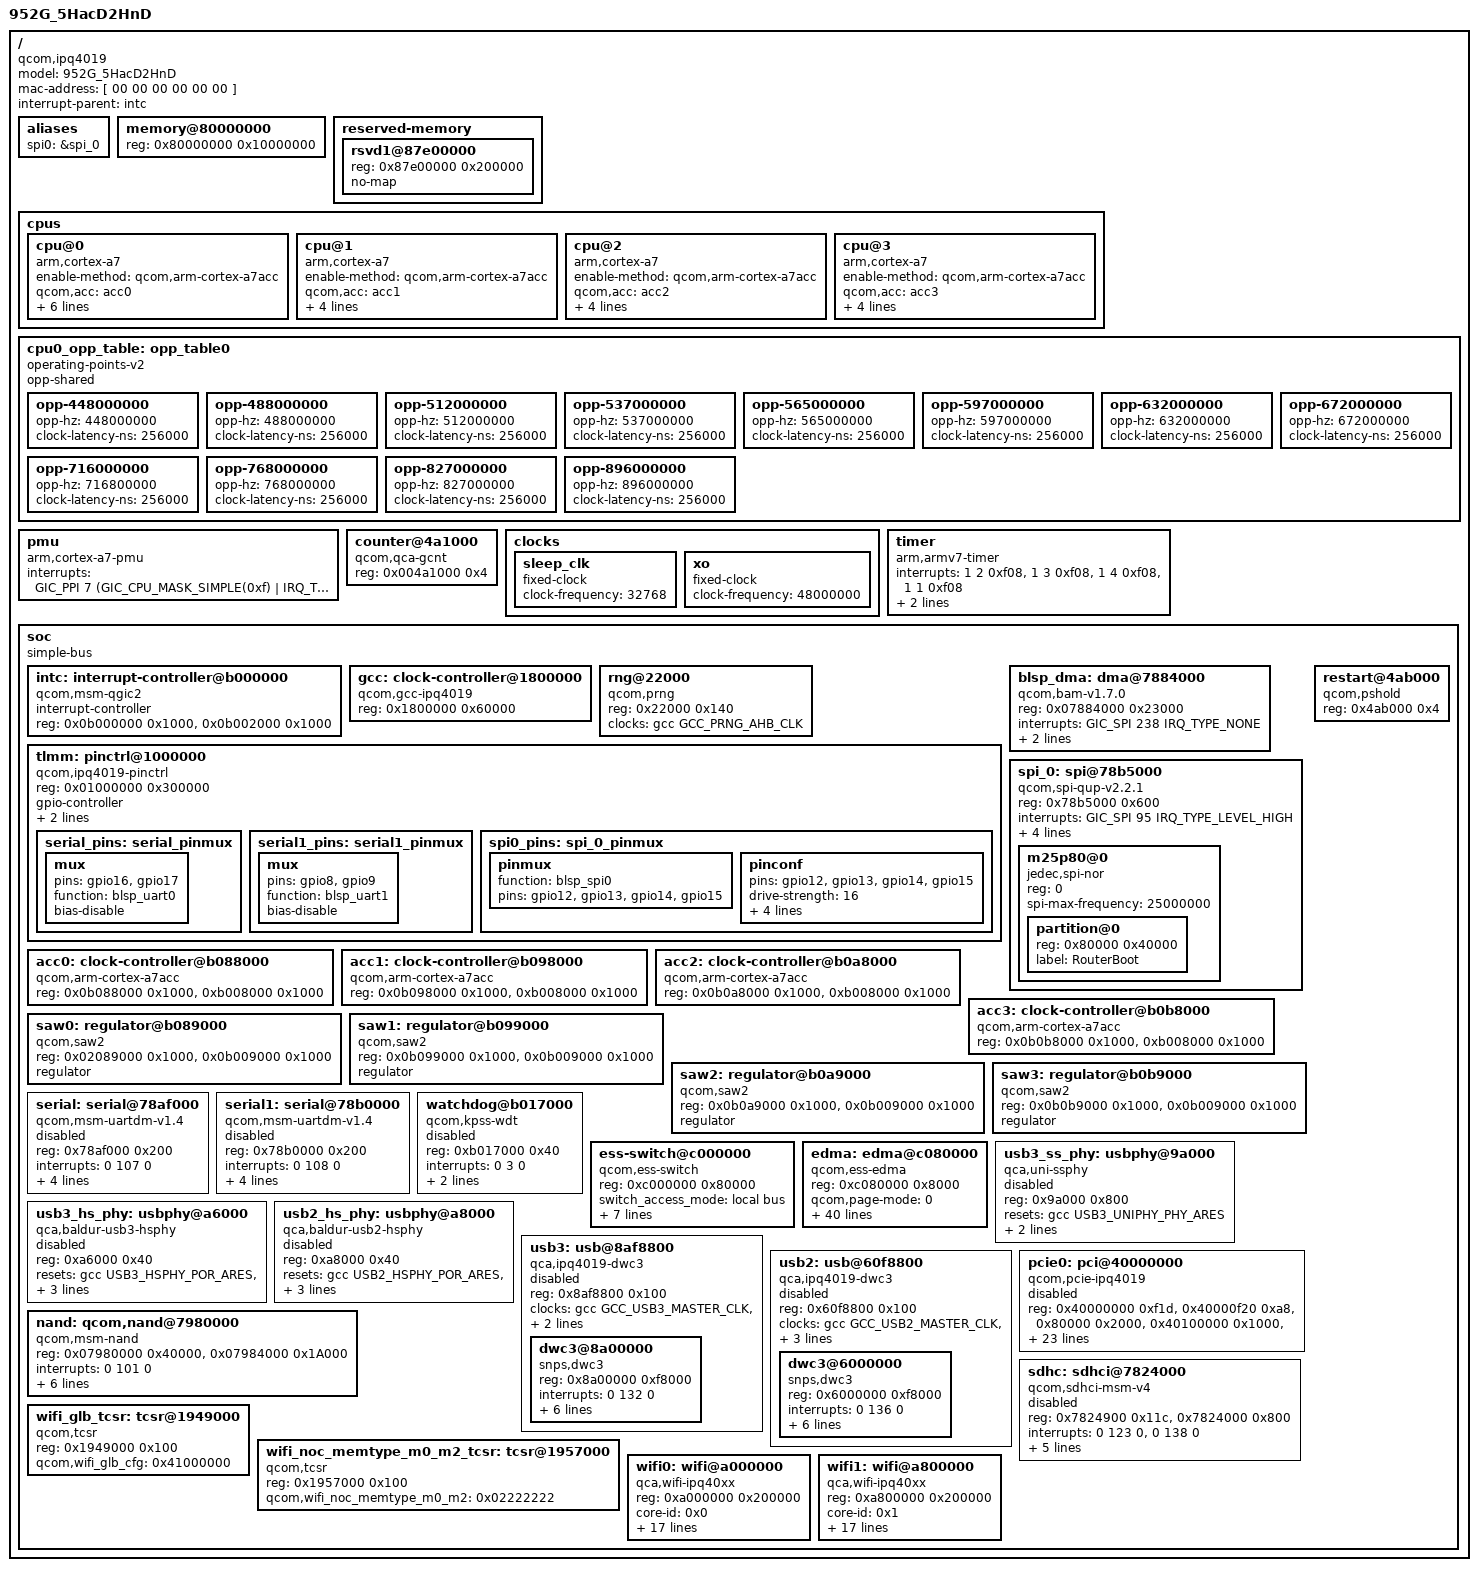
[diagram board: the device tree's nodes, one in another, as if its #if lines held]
#include <dt-bindings/clock/qcom,gcc-ipq4019.h>
#include <dt-bindings/interrupt-controller/arm-gic.h>
#include <dt-bindings/interrupt-controller/irq.h>
#include <dt-bindings/gpio/gpio.h>
#include "dakota_crypto.dtsi"

/ {
	#address-cells = <1>;
	#size-cells = <1>;
	
	model = "952G_5HacD2HnD";
	compatible = "qcom,ipq4019";
	mac-address = [ 00 00 00 00 00 00 ];
	interrupt-parent = <&intc>;

	aliases {
		spi0 = &spi_0;
	};

	memory@80000000 {
		device_type = "memory";
		reg = <0x80000000 0x10000000>; /* 256MB */
	};

	reserved-memory {
		#address-cells = <1>;
		#size-cells = <1>;
		ranges;
		rsvd1@87e00000 {
			reg = <0x87e00000 0x200000>;
			no-map;
		};
	};

	cpus {
		#address-cells = <1>;
		#size-cells = <0>;
		cpu@0 {
			device_type = "cpu";
			compatible = "arm,cortex-a7";
			enable-method = "qcom,arm-cortex-a7acc";
			qcom,acc = <&acc0>;
			qcom,saw = <&saw0>;
			reg = <0x0>;
			clocks = <&gcc GCC_APPS_CLK_SRC>;
			clock-frequency = <0>;
			operating-points-v2 = <&cpu0_opp_table>;
			clock-latency = <256000>;
		};

		cpu@1 {
			device_type = "cpu";
			compatible = "arm,cortex-a7";
			enable-method = "qcom,arm-cortex-a7acc";
			qcom,acc = <&acc1>;
			qcom,saw = <&saw1>;
			reg = <0x1>;
			clocks = <&gcc GCC_APPS_CLK_SRC>;
			clock-frequency = <0>;
		};

		cpu@2 {
			device_type = "cpu";
			compatible = "arm,cortex-a7";
			enable-method = "qcom,arm-cortex-a7acc";
			qcom,acc = <&acc2>;
			qcom,saw = <&saw2>;
			reg = <0x2>;
			clocks = <&gcc GCC_APPS_CLK_SRC>;
			clock-frequency = <0>;
		};

		cpu@3 {
			device_type = "cpu";
			compatible = "arm,cortex-a7";
			enable-method = "qcom,arm-cortex-a7acc";
			qcom,acc = <&acc3>;
			qcom,saw = <&saw3>;
			reg = <0x3>;
			clocks = <&gcc GCC_APPS_CLK_SRC>;
			clock-frequency = <0>;
		};
	};

	cpu0_opp_table: opp_table0 {
		compatible = "operating-points-v2";
		opp-shared;

		opp-448000000 {
			opp-hz = /bits/ 64 <448000000>;
			clock-latency-ns = <256000>;
		};
		opp-488000000 {
			opp-hz = /bits/ 64 <488000000>;
			clock-latency-ns = <256000>;
		};
		opp-512000000 {
			opp-hz = /bits/ 64 <512000000>;
			clock-latency-ns = <256000>;
		};
		opp-537000000 {
			opp-hz = /bits/ 64 <537000000>;
			clock-latency-ns = <256000>;
		};
		opp-565000000 {
			opp-hz = /bits/ 64 <565000000>;
			clock-latency-ns = <256000>;
		};
		opp-597000000 {
			opp-hz = /bits/ 64 <597000000>;
			clock-latency-ns = <256000>;
		};
		opp-632000000 {
			opp-hz = /bits/ 64 <632000000>;
			clock-latency-ns = <256000>;
		};
		opp-672000000 {
			opp-hz = /bits/ 64 <672000000>;
			clock-latency-ns = <256000>;
		};
		opp-716000000 {
			opp-hz = /bits/ 64 <716800000>;
			clock-latency-ns = <256000>;
		};
		opp-768000000 {
			opp-hz = /bits/ 64 <768000000>;
			clock-latency-ns = <256000>;
		};
		opp-827000000 {
			opp-hz = /bits/ 64 <827000000>;
			clock-latency-ns = <256000>;
		};
		opp-896000000 {
			opp-hz = /bits/ 64 <896000000>;
			clock-latency-ns = <256000>;
		};
	};

	pmu {
		compatible = "arm,cortex-a7-pmu";
		interrupts = <GIC_PPI 7 (GIC_CPU_MASK_SIMPLE(0xf) |
					 IRQ_TYPE_LEVEL_HIGH)>;
	};

	counter@4a1000 {
		compatible = "qcom,qca-gcnt";
		reg = <0x004a1000 0x4>;
	};

	clocks {
		sleep_clk: sleep_clk {
			compatible = "fixed-clock";
			clock-frequency = <32768>;
			#clock-cells = <0>;
		};

		xo: xo {
			compatible = "fixed-clock";
			clock-frequency = <48000000>;
			#clock-cells = <0>;
		};
	};

	timer {
		compatible = "arm,armv7-timer";
		interrupts = <1 2 0xf08>,
			     <1 3 0xf08>,
			     <1 4 0xf08>,
			     <1 1 0xf08>;
		clock-frequency = <48000000>;
		always-on;
	};

	soc: soc {
		#address-cells = <1>;
		#size-cells = <1>;
		ranges;
		compatible = "simple-bus";

		intc: interrupt-controller@b000000 {
			compatible = "qcom,msm-qgic2";
			interrupt-controller;
			#interrupt-cells = <3>;
			reg = <0x0b000000 0x1000>,
			<0x0b002000 0x1000>;
		};

		gcc: clock-controller@1800000 {
			compatible = "qcom,gcc-ipq4019";
			#clock-cells = <1>;
			#reset-cells = <1>;
			reg = <0x1800000 0x60000>;
		};

		rng@22000 {
			compatible = "qcom,prng";
			reg = <0x22000 0x140>;
			clocks = <&gcc GCC_PRNG_AHB_CLK>;
			clock-names = "core";
		};

		tlmm: pinctrl@1000000 {
			compatible = "qcom,ipq4019-pinctrl";
			reg = <0x01000000 0x300000>;
			gpio-controller;
			#gpio-cells = <2>;
			interrupt-controller;
			#interrupt-cells = <2>;
			interrupts = <0 208 0>;

			serial_pins: serial_pinmux {
				mux {
#ifdef BIG_DK 
					pins = "gpio16", "gpio17";
					function = "blsp_uart0";
					bias-disable;
#else
					pins = "gpio60", "gpio61";
					function = "blsp_uart0";
					bias-disable;
#endif
				};
			};

			serial1_pins: serial1_pinmux {
				mux {
					pins = "gpio8", "gpio9";
					function = "blsp_uart1";
					bias-disable;
				};
			};

			spi0_pins: spi_0_pinmux {
#ifdef BIG_DK 
				pinmux {
					function = "blsp_spi0";
					pins = "gpio12", "gpio13", "gpio14", "gpio15";
				};
				pinconf {
					pins = "gpio12", "gpio13", "gpio14", "gpio15";
					drive-strength = <16>;
					bias-pull-up;
					bias-pull-down;
					vm-enable;
					pull-res = <2>;
				};
#else
				pinmux {
					function = "blsp_spi0";
					pins = "gpio54", "gpio55", "gpio56", "gpio57";
				};
				pinconf {
					pins = "gpio54", "gpio55", "gpio56", "gpio57";
					drive-strength = <16>;
					bias-pull-up;
					bias-pull-down;
					vm-enable;
					pull-res = <2>;
				};
#endif
			};
		};

		blsp_dma: dma@7884000 {
			compatible = "qcom,bam-v1.7.0";
			reg = <0x07884000 0x23000>;
			interrupts = <GIC_SPI 238 IRQ_TYPE_NONE>;
			clocks = <&gcc GCC_BLSP1_AHB_CLK>;
			clock-names = "bam_clk";
			#dma-cells = <1>;
			qcom,ee = <0>;
		};

		spi_0: spi@78b5000 {
			compatible = "qcom,spi-qup-v2.2.1";
			reg = <0x78b5000 0x600>;
			interrupts = <GIC_SPI 95 IRQ_TYPE_LEVEL_HIGH>;
			clocks = <&gcc GCC_BLSP1_QUP1_SPI_APPS_CLK>,
				 <&gcc GCC_BLSP1_AHB_CLK>;
			clock-names = "core", "iface";
			#address-cells = <1>;
			#size-cells = <0>;

			dmas = <&blsp_dma 5>, <&blsp_dma 4>;
			dma-names = "rx", "tx";

			pinctrl-0 = <&spi0_pins>;
			pinctrl-names = "default";

			m25p80@0 {
				#address-cells = <1>;
				#size-cells = <1>;
				compatible = "jedec,spi-nor";
				reg = <0>;
				spi-max-frequency = <25000000>;

#ifdef NAND
				partition@0 {
					reg = <0x80000 0x40000>;
					label = "RouterBoot";
				};
#else
				partition@0 {
					reg = <0x100000 0>;
					label = "RouterOS";
				};
				partition@1 {
					reg = <0x80000 0x40000>;
					label = "RouterBoot";
				};
#endif
			};
		};

                acc0: clock-controller@b088000 {
                        compatible = "qcom,arm-cortex-a7acc";
                        reg = <0x0b088000 0x1000>, <0xb008000 0x1000>;
                };

                acc1: clock-controller@b098000 {
                        compatible = "qcom,arm-cortex-a7acc";
                        reg = <0x0b098000 0x1000>, <0xb008000 0x1000>;
                };

                acc2: clock-controller@b0a8000 {
                        compatible = "qcom,arm-cortex-a7acc";
                        reg = <0x0b0a8000 0x1000>, <0xb008000 0x1000>;
                };

                acc3: clock-controller@b0b8000 {
                        compatible = "qcom,arm-cortex-a7acc";
                        reg = <0x0b0b8000 0x1000>, <0xb008000 0x1000>;
                };

                saw0: regulator@b089000 {
                        compatible = "qcom,saw2";
                        reg = <0x02089000 0x1000>, <0x0b009000 0x1000>;
                        regulator;
                };

                saw1: regulator@b099000 {
                        compatible = "qcom,saw2";
                        reg = <0x0b099000 0x1000>, <0x0b009000 0x1000>;
                        regulator;
                };

                saw2: regulator@b0a9000 {
                        compatible = "qcom,saw2";
                        reg = <0x0b0a9000 0x1000>, <0x0b009000 0x1000>;
                        regulator;
                };

                saw3: regulator@b0b9000 {
                        compatible = "qcom,saw2";
                        reg = <0x0b0b9000 0x1000>, <0x0b009000 0x1000>;
                        regulator;
                };

		serial: serial@78af000 {
			compatible = "qcom,msm-uartdm-v1.4", "qcom,msm-uartdm";
			reg = <0x78af000 0x200>;
			interrupts = <0 107 0>;
			clocks = <&gcc GCC_BLSP1_UART1_APPS_CLK>,
				<&gcc GCC_BLSP1_AHB_CLK>;
			clock-names = "core", "iface";
			dmas = <&blsp_dma 1>, <&blsp_dma 0>;
			dma-names = "rx", "tx";
			pinctrl-0 = <&serial_pins>;
			pinctrl-names = "default";
			status = "disabled";
		};

		serial1: serial@78b0000 {
			compatible = "qcom,msm-uartdm-v1.4", "qcom,msm-uartdm";
			reg = <0x78b0000 0x200>;
			interrupts = <0 108 0>;
			clocks = <&gcc GCC_BLSP1_UART2_APPS_CLK>,
				<&gcc GCC_BLSP1_AHB_CLK>;
			clock-names = "core", "iface";
			dmas = <&blsp_dma 3>, <&blsp_dma 2>;
			dma-names = "rx", "tx";
			pinctrl-0 = <&serial1_pins>;
			pinctrl-names = "default";
			status = "disabled";
		};

		watchdog@b017000 {
			compatible = "qcom,kpss-wdt",
				     "qcom,kpss-wdt-ipq4019";
			reg = <0xb017000 0x40>;
			interrupt-names = "bark_irq";
			interrupts = <0 3 0>;
			clocks = <&sleep_clk>;
			timeout-sec = <10>;
			status = "disabled";
		};

		restart@4ab000 {
			compatible = "qcom,pshold";
			reg = <0x4ab000 0x4>;
		};
		
		ess-switch@c000000 {
			compatible = "qcom,ess-switch";
			reg = <0xc000000 0x80000>; /* 512KB */
			switch_access_mode = "local bus";
			resets = <&gcc 29>, <&gcc 78>, <&gcc 79>,
			         <&gcc 80>, <&gcc 81>, <&gcc 82>;
			reset-names = "ess_rst","ess_mac1_clk_dis",
				      "ess_mac2_clk_dis","ess_mac3_clk_dis",
				      "ess_mac4_clk_dis", "ess_mac5_clk_dis";
//			clocks = <&gcc GCC_ESS_CLK>;
//			clock-names = "ess_clk";
			switch_cpu_bmp = <0x1>;  /* cpu port bitmap */
			switch_lan_bmp = <0x1e>; /* lan port bitmap */
			switch_wan_bmp = <0x20>; /* wan port bitmap */
			switch_mac_mode = <0x0>; /* mac mode for RGMII RMII */
			switch_initvlas = <0x0007c 0x54>; /* PORT0_STATUS */
		};
		edma: edma@c080000 {
			compatible = "qcom,ess-edma";
			reg = <0xc080000 0x8000>;
			qcom,page-mode = <0>;
			qcom,rx_head_buf_size = <1540>;
			qcom,wan_port_id_mask = <0x10>;
			qcom,mdio_supported;
			qcom,phy_mdio_addr = <4>;
			qcom,poll_required = <1>;
			qcom,forced_speed = <1000>;
			qcom,forced_duplex = <1>;

			interrupts = <0 65 IRQ_TYPE_EDGE_RISING>,
				     <0 66 IRQ_TYPE_EDGE_RISING>,
				     <0 67 IRQ_TYPE_EDGE_RISING>,
				     <0 68 IRQ_TYPE_EDGE_RISING>,
				     <0 69 IRQ_TYPE_EDGE_RISING>,
				     <0 70 IRQ_TYPE_EDGE_RISING>,
				     <0 71 IRQ_TYPE_EDGE_RISING>,
				     <0 72 IRQ_TYPE_EDGE_RISING>,
				     <0 73 IRQ_TYPE_EDGE_RISING>,
				     <0 74 IRQ_TYPE_EDGE_RISING>,
				     <0 75 IRQ_TYPE_EDGE_RISING>,
				     <0 76 IRQ_TYPE_EDGE_RISING>,
				     <0 77 IRQ_TYPE_EDGE_RISING>,
				     <0 78 IRQ_TYPE_EDGE_RISING>,
				     <0 79 IRQ_TYPE_EDGE_RISING>,
				     <0 80 IRQ_TYPE_EDGE_RISING>,
				     <0 240 IRQ_TYPE_EDGE_RISING>,
				     <0 241 IRQ_TYPE_EDGE_RISING>,
				     <0 242 IRQ_TYPE_EDGE_RISING>,
				     <0 243 IRQ_TYPE_EDGE_RISING>,
				     <0 244 IRQ_TYPE_EDGE_RISING>,
				     <0 245 IRQ_TYPE_EDGE_RISING>,
				     <0 246 IRQ_TYPE_EDGE_RISING>,
				     <0 247 IRQ_TYPE_EDGE_RISING>,
				     <0 248 IRQ_TYPE_EDGE_RISING>,
				     <0 249 IRQ_TYPE_EDGE_RISING>,
				     <0 250 IRQ_TYPE_EDGE_RISING>,
				     <0 251 IRQ_TYPE_EDGE_RISING>,
				     <0 252 IRQ_TYPE_EDGE_RISING>,
				     <0 253 IRQ_TYPE_EDGE_RISING>,
				     <0 254 IRQ_TYPE_EDGE_RISING>,
				     <0 255 IRQ_TYPE_EDGE_RISING>;
			clocks = <&gcc GCC_ESS_CLK>;
			clock-names = "ess_clk";
		};

		usb3_ss_phy: usbphy@9a000 {
			compatible = "qca,uni-ssphy";
			reg = <0x9a000 0x800>;
			reg-names = "phy_base";
			resets = <&gcc USB3_UNIPHY_PHY_ARES>;
			reset-names = "por_rst";
			qca,emulation = <0>;
			qca,host = <1>;
			status = "disabled";
		};

		usb3_hs_phy: usbphy@a6000 {
			compatible = "qca,baldur-usb3-hsphy";
			reg = <0xa6000 0x40>;
			reg-names = "phy_base";
			resets = <&gcc USB3_HSPHY_POR_ARES>, <&gcc USB3_HSPHY_S_ARES>;
			reset-names = "por_rst", "srif_rst";
			qca,emulation = <0>;
			qca,host = <1>;
			status = "disabled";
		};

		usb2_hs_phy: usbphy@a8000 {
			compatible = "qca,baldur-usb2-hsphy";
			reg = <0xa8000 0x40>;
			reg-names = "phy_base";
			resets = <&gcc USB2_HSPHY_POR_ARES>, <&gcc USB2_HSPHY_S_ARES>;
			reset-names = "por_rst", "srif_rst";
			qca,emulation = <0>;
			qca,host = <1>;
			status = "disabled";
		};

		usb3: usb@8af8800 {
			compatible = "qca,ipq4019-dwc3";
			reg = <0x8af8800 0x100>;
			#address-cells = <1>;
			#size-cells = <1>;
			clocks = <&gcc GCC_USB3_MASTER_CLK>,
				 <&gcc GCC_USB3_SLEEP_CLK>,
				 <&gcc GCC_USB3_MOCK_UTMI_CLK>;
			clock-names = "core", "sleep", "mock_utmi";
			ranges;
			status = "disabled";

			dwc3@8a00000 {
				compatible = "snps,dwc3";
				reg = <0x8a00000 0xf8000>;
				interrupts = <0 132 0>;
				usb-phy = <&usb3_hs_phy>, <&usb3_ss_phy>;
				phy-names = "usb2-phy", "usb3-phy";
				dr_mode = "host";
				usb2-susphy-quirk;
				snps,dis_u3_susphy_quirk;
				snps,dis_u2_susphy_quirk;
				snps,parkmode-disable-ss-quirk;
			};
		};

		usb2: usb@60f8800 {
			compatible = "qca,ipq4019-dwc3";
			reg = <0x60f8800 0x100>;
			#address-cells = <1>;
			#size-cells = <1>;
			clocks = <&gcc GCC_USB2_MASTER_CLK>,
				 <&gcc GCC_USB2_SLEEP_CLK>,
				 <&gcc GCC_USB2_MOCK_UTMI_CLK>;
			clock-names = "core", "sleep", "mock_utmi";
			ranges;
			qcom,select-utmi-as-pipe-clk;
			status = "disabled";

			dwc3@6000000 {
				compatible = "snps,dwc3";
				reg = <0x6000000 0xf8000>;
				interrupts = <0 136 0>;
				usb-phy = <&usb2_hs_phy>;
				phy-names = "usb2-phy";
				dr_mode = "host";
				usb2-susphy-quirk;
				snps,dis_u3_susphy_quirk;
				snps,dis_u2_susphy_quirk;
				snps,parkmode-disable-ss-quirk;
			};
		};

		pcie0: pci@40000000 {
			compatible = "qcom,pcie-ipq4019";

			reg =  <0x40000000 0xf1d>,
				<0x40000f20 0xa8>,
				<0x80000 0x2000>,
				<0x40100000 0x1000>,
				<0x99000 0x800>;
			reg-names = "dbi", "elbi", "parf", "config", "pciephy";
			device_type = "pci";
			linux,pci-domain = <0>;
			bus-range = <0x00 0xff>;
			num-lanes = <1>;
			#address-cells = <3>;
			#size-cells = <2>;

			ranges = <0x81000000 0 0x40200000 0x40200000 0 0x00100000>,   /* I/O */
				<0x82000010 0 0x40300000 0x40300000 0 0x00d00000>; /* MEM */

			interrupts = <0 141 0>;
			interrupt-names = "msi";
			#interrupt-cells = <1>;
			interrupt-map-mask = <0 0 0 0x7>;
			interrupt-map = <0 0 0 1 &intc 0 142 IRQ_TYPE_LEVEL_HIGH>, /* int_a */
					<0 0 0 2 &intc 0 143 IRQ_TYPE_LEVEL_HIGH>, /* int_b */
					<0 0 0 3 &intc 0 144 IRQ_TYPE_LEVEL_HIGH>, /* int_c */
					<0 0 0 4 &intc 0 145 IRQ_TYPE_LEVEL_HIGH>; /* int_d */
			clocks = <&gcc GCC_PCIE_AHB_CLK>,
				<&gcc GCC_PCIE_AXI_M_CLK>,
				<&gcc GCC_PCIE_AXI_S_CLK>;
			clock-names = "aux",
				"master_bus",
				"slave_bus";

			resets = <&gcc PCIE_AXI_M_ARES>,
				<&gcc PCIE_AXI_S_ARES>,
				<&gcc PCIE_PIPE_ARES>,
				<&gcc PCIE_AXI_M_VMIDMT_ARES>,
				<&gcc PCIE_AXI_S_XPU_ARES>,
				<&gcc PCIE_PARF_XPU_ARES>,
				<&gcc PCIE_PHY_ARES>,
				<&gcc PCIE_AXI_M_STICKY_ARES>,
				<&gcc PCIE_PIPE_STICKY_ARES>,
				<&gcc PCIE_PWR_ARES>,
				<&gcc PCIE_AHB_ARES>,
				<&gcc PCIE_PHY_AHB_ARES>;
			reset-names = "axi_m",
				"axi_s",
				"pipe",
				"axi_m_vmid",
				"axi_s_xpu",
				"parf",
				"phy",
				"axi_m_sticky",
				"pipe_sticky",
				"pwr",
				"ahb",
				"phy_ahb";
			status = "disabled";
		};

		nand: qcom,nand@7980000 {
			compatible = "qcom,msm-nand";
			reg = <0x07980000 0x40000>,
				<0x07984000 0x1A000>;
			reg-names = "nand_phys",
				"bam_phys";
			interrupts = <0 101 0>;
			interrupt-names = "bam_irq";
			qcom,msm-bus,name = "qpic_nand";
			qcom,msm-bus,num-cases = <2>;
			qcom,msm-bus,num-paths = <1>;
			qcom,msm-bus,vectors-KBps =
						<91 512 0 0>,
						/* Voting for max b/w on PNOC bus for now */
						<91 512 400000 800000>;
			clock-names = "iface_clk", "core_clk";
			clocks = <&gcc GCC_QPIC_AHB_CLK>,
				<&gcc GCC_QPIC_CLK>;
#ifdef NAND
			status = "ok";
#else
			status = "disabled";
#endif
		};

		sdhc: sdhci@7824000 {
			compatible = "qcom,sdhci-msm-v4";
			reg = <0x7824900 0x11c>, <0x7824000 0x800>;
			reg-names = "hc_mem", "core_mem";
			interrupts = <0 123 0>, <0 138 0>;
			interrupt-names = "hc_irq", "pwr_irq";
			bus-width = <8>;
			clocks = <&gcc GCC_SDCC1_APPS_CLK>, <&gcc GCC_SDCC1_AHB_CLK>;
			clock-names = "core", "iface";
		
			cpu-ipq40xx;
		
			cd-gpios = <&tlmm 22 GPIO_ACTIVE_LOW>;
			status = "disabled";
		};

		wifi_glb_tcsr: tcsr@1949000 {
			compatible = "qcom,tcsr";
			reg = <0x1949000 0x100>;
			qcom,wifi_glb_cfg = <0x41000000>;
		};

		wifi_noc_memtype_m0_m2_tcsr: tcsr@1957000 {
			compatible = "qcom,tcsr";
			reg = <0x1957000 0x100>;
			qcom,wifi_noc_memtype_m0_m2 = <0x02222222>;
		};

		wifi0: wifi@a000000 {
			compatible = "qca,wifi-ipq40xx";
			reg = <0xa000000 0x200000>;
			core-id = <0x0>;
			resets = <&gcc WIFI0_CPU_INIT_RESET>,
				<&gcc WIFI0_RADIO_SRIF_RESET>,
				<&gcc WIFI0_RADIO_WARM_RESET>,
				<&gcc WIFI0_RADIO_COLD_RESET>,
				<&gcc WIFI0_CORE_WARM_RESET>,
				<&gcc WIFI0_CORE_COLD_RESET>;
			reset-names = "wifi_cpu_init",
				"wifi_radio_srif",
				"wifi_radio_warm",
				"wifi_radio_cold",
				"wifi_core_warm",
				"wifi_core_cold";
			clocks = <&gcc GCC_WCSS2G_CLK>,
				<&gcc GCC_WCSS2G_REF_CLK>,
				<&gcc GCC_WCSS2G_RTC_CLK>;
			clock-names = "wifi_wcss_cmd", "wifi_wcss_ref", "wifi_wcss_rtc";
			interrupts = <0 0x20 0x1>,
				<0 0x21 0x1>,
				<0 0x22 0x1>,
				<0 0x23 0x1>,
				<0 0x24 0x1>,
				<0 0x25 0x1>,
				<0 0x26 0x1>,
				<0 0x27 0x1>,
				<0 0x28 0x1>,
				<0 0x29 0x1>,
				<0 0x2a 0x1>,
				<0 0x2b 0x1>,
				<0 0x2c 0x1>,
				<0 0x2d 0x1>,
				<0 0x2e 0x1>,
				<0 0x2f 0x1>,
				<0 0xa8 0x0>;
			interrupt-names = "msi0", "msi1", "msi2", "msi3", "msi4", "msi5", "msi6",
				"msi7", "msi8", "msi9", "msi10", "msi11", "msi12", "msi13", "msi14",
				"msi15", "legacy";
			status = "ok";
			qca,msi_addr = <0x0b006040>;
			qca,msi_base = <0x40>;
		};

		wifi1: wifi@a800000 {
			compatible = "qca,wifi-ipq40xx";
			reg = <0xa800000 0x200000>;
			core-id = <0x1>;
			resets = <&gcc WIFI1_CPU_INIT_RESET>,
				<&gcc WIFI1_RADIO_SRIF_RESET>,
				<&gcc WIFI1_RADIO_WARM_RESET>,
				<&gcc WIFI1_RADIO_COLD_RESET>,
				<&gcc WIFI1_CORE_WARM_RESET>,
				<&gcc WIFI1_CORE_COLD_RESET>;
			reset-names = "wifi_cpu_init",
				"wifi_radio_srif",
				"wifi_radio_warm",
				"wifi_radio_cold",
				"wifi_core_warm",
				"wifi_core_cold";
			clocks = <&gcc GCC_WCSS5G_CLK>,
				<&gcc GCC_WCSS5G_REF_CLK>,
				<&gcc GCC_WCSS5G_RTC_CLK>;
			clock-names = "wifi_wcss_cmd", "wifi_wcss_ref", "wifi_wcss_rtc";
			interrupts = <0 0x30 0x1>,
				<0 0x31 0x1>,
				<0 0x32 0x1>,
				<0 0x33 0x1>,
				<0 0x34 0x1>,
				<0 0x35 0x1>,
				<0 0x36 0x1>,
				<0 0x37 0x1>,
				<0 0x38 0x1>,
				<0 0x39 0x1>,
				<0 0x3a 0x1>,
				<0 0x3b 0x1>,
				<0 0x3c 0x1>,
				<0 0x3d 0x1>,
				<0 0x3e 0x1>,
				<0 0x3f 0x1>,
				<0 0xa9 0x0>;
			interrupt-names = "msi0", "msi1", "msi2", "msi3", "msi4", "msi5", "msi6",
				"msi7", "msi8", "msi9", "msi10", "msi11", "msi12", "msi13", "msi14",
				"msi15", "legacy";
			status = "ok";
			qca,msi_addr = <0x0b006040>;
			qca,msi_base = <0x50>;
		};
	};
};

